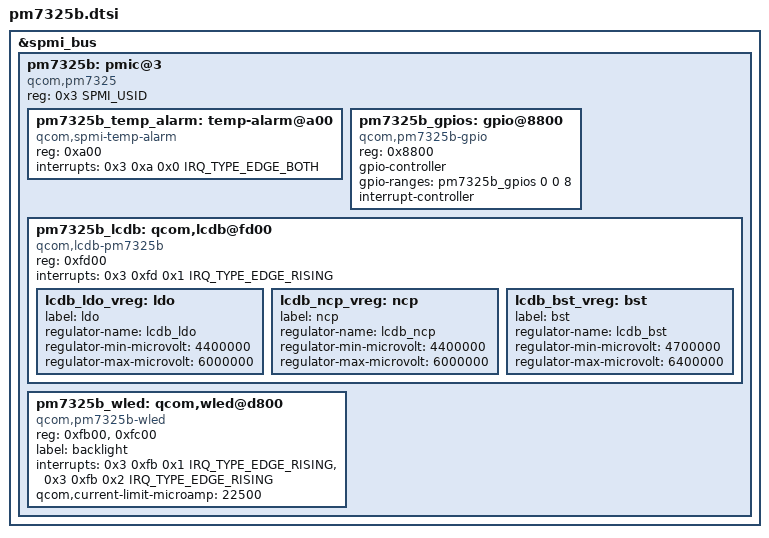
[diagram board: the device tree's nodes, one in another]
// SPDX-License-Identifier: BSD-3-Clause
/*
 * Copyright (c) 2023 Qualcomm Innovation Center, Inc. All rights reserved.
 */

#include <dt-bindings/iio/qcom,spmi-vadc.h>
#include <dt-bindings/interrupt-controller/irq.h>
#include <dt-bindings/spmi/spmi.h>

&spmi_bus {
	pm7325b: pmic@3 {
		compatible = "qcom,pm7325", "qcom,spmi-pmic";
		reg = <0x3 SPMI_USID>;
		#address-cells = <1>;
		#size-cells = <0>;

		pm7325b_temp_alarm: temp-alarm@a00 {
			compatible = "qcom,spmi-temp-alarm";
			reg = <0xa00>;
			interrupts = <0x3 0xa 0x0 IRQ_TYPE_EDGE_BOTH>;
			#thermal-sensor-cells = <0>;
		};

		pm7325b_gpios: gpio@8800 {
			compatible = "qcom,pm7325b-gpio", "qcom,spmi-gpio";
			reg = <0x8800>;
			gpio-controller;
			gpio-ranges = <&pm7325b_gpios 0 0 8>;
			#gpio-cells = <2>;
			interrupt-controller;
			#interrupt-cells = <2>;
		};

		pm7325b_lcdb: qcom,lcdb@fd00 {
			compatible = "qcom,lcdb-pm7325b";
			#address-cells = <1>;
			#size-cells = <0>;
			reg = <0xfd00>;
			interrupts = <0x3 0xfd 0x1 IRQ_TYPE_EDGE_RISING>;
			interrupt-names = "sc-irq";

			lcdb_ldo_vreg: ldo {
				label = "ldo";
				regulator-name = "lcdb_ldo";
				regulator-min-microvolt = <4400000>;
				regulator-max-microvolt = <6000000>;
			};

			lcdb_ncp_vreg: ncp {
				label = "ncp";
				regulator-name = "lcdb_ncp";
				regulator-min-microvolt = <4400000>;
				regulator-max-microvolt = <6000000>;
			};

			lcdb_bst_vreg: bst {
				label = "bst";
				regulator-name = "lcdb_bst";
				regulator-min-microvolt = <4700000>;
				regulator-max-microvolt = <6400000>;
			};
		};

		pm7325b_wled: qcom,wled@d800 {
			compatible = "qcom,pm7325b-wled";
			reg = <0xfb00>, <0xfc00>;
			reg-names = "wled-ctrl-base", "wled-sink-base";
			label = "backlight";
			interrupts = <0x3 0xfb 0x1 IRQ_TYPE_EDGE_RISING>,
					<0x3 0xfb 0x2 IRQ_TYPE_EDGE_RISING>;
			interrupt-names = "ovp", "short";
			qcom,current-limit-microamp = <22500>;
		};
	};
};
